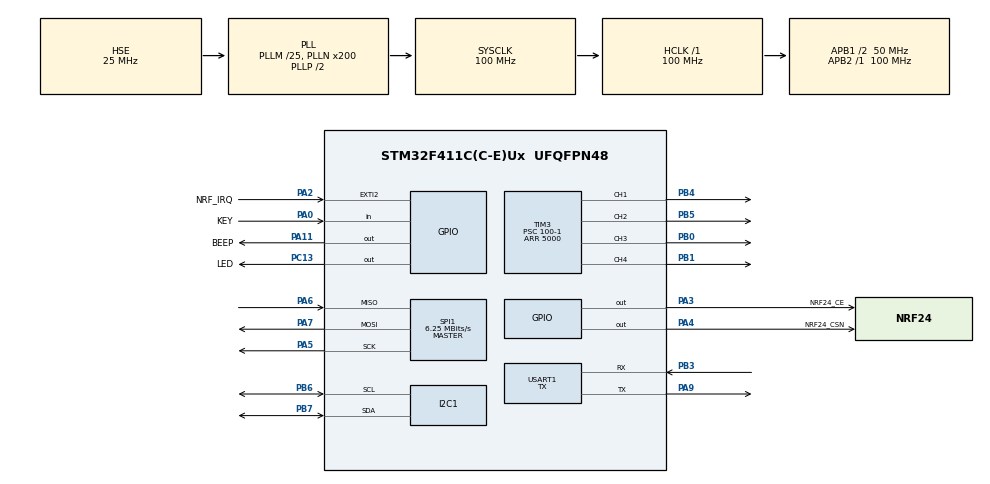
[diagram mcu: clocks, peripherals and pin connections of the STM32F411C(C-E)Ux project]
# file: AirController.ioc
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FREERTOS.BinarySemaphores01=NrfIT_Binary,Dynamic,NULL
FREERTOS.Events01=CanFlyEvent,Dynamic,NULL
FREERTOS.Queues01=rxQueue,10,12,1,Dynamic,NULL,NULL
FREERTOS.Tasks01=MainTask,42,256,StartDefaultTask,Default,NULL,Dynamic,NULL,NULL;Link2RemTask,32,512,linkTask,Default,NULL,Dynamic,NULL,NULL;ControlTask,24,512,controlTask,Default,NULL,Dynamic,NULL,NULL
FREERTOS.configENABLE_FPU=1
FREERTOS.configUSE_NEWLIB_REENTRANT=0
Mcu.Family=STM32F4
Mcu.Name=STM32F411C(C-E)Ux
Mcu.Package=UFQFPN48
NVIC.EXTI2_IRQn=true\:5\:0\:true\:false\:true\:true\:true\:true
NVIC.I2C1_ER_IRQn=true\:5\:0\:false\:false\:true\:true\:true\:true
NVIC.I2C1_EV_IRQn=true\:5\:0\:true\:false\:true\:true\:true\:true
NVIC.PriorityGroup=NVIC_PRIORITYGROUP_4
NVIC.SPI1_IRQn=true\:5\:0\:false\:false\:true\:true\:true\:true
NVIC.TIM1_UP_TIM10_IRQn=true\:0\:0\:false\:false\:true\:false\:false\:true
NVIC.TIM3_IRQn=true\:5\:0\:false\:false\:true\:true\:true\:true
NVIC.TimeBase=TIM1_UP_TIM10_IRQn
NVIC.TimeBaseIP=TIM1
PA0-WKUP.GPIO_Label=KEY
PA0-WKUP.GPIO_PuPd=GPIO_PULLUP
PA0-WKUP.Signal=GPIO_Input
PA11.GPIO_Label=BEEP
PA11.GPIO_PuPd=GPIO_PULLUP
PA11.GPIO_Speed=GPIO_SPEED_FREQ_LOW
PA11.Signal=GPIO_Output
PA13.Mode=Serial_Wire
PA13.Signal=SYS_JTMS-SWDIO
PA14.Mode=Serial_Wire
PA14.Signal=SYS_JTCK-SWCLK
PA2.GPIO_Label=NRF_IRQ
PA2.GPIO_ModeDefaultEXTI=GPIO_MODE_IT_FALLING
PA2.GPIO_PuPd=GPIO_PULLUP
PA2.Signal=GPXTI2
PA3.GPIO_Label=NRF24_CE
PA3.GPIO_ModeDefaultOutputPP=GPIO_MODE_OUTPUT_PP
PA3.GPIO_PuPd=GPIO_PULLUP
PA3.GPIO_Speed=GPIO_SPEED_FREQ_LOW
PA3.PinState=GPIO_PIN_SET
PA3.Signal=GPIO_Output
PA4.GPIO_Label=NRF24_CSN
PA4.GPIO_ModeDefaultOutputPP=GPIO_MODE_OUTPUT_PP
PA4.GPIO_PuPd=GPIO_PULLUP
PA4.GPIO_Speed=GPIO_SPEED_FREQ_LOW
PA4.PinState=GPIO_PIN_SET
PA4.Signal=GPIO_Output
PA5.Mode=Full_Duplex_Master
PA5.Signal=SPI1_SCK
PA6.Mode=Full_Duplex_Master
PA6.Signal=SPI1_MISO
PA7.Mode=Full_Duplex_Master
PA7.Signal=SPI1_MOSI
PA9.Mode=Asynchronous
PA9.Signal=USART1_TX
PB0.Signal=S_TIM3_CH3
PB1.Signal=S_TIM3_CH4
PB3.Mode=Asynchronous
PB3.Signal=USART1_RX
PB4.Signal=S_TIM3_CH1
PB5.Signal=S_TIM3_CH2
PB6.GPIO_Pu=GPIO_PULLUP
PB6.Mode=I2C
PB6.Signal=I2C1_SCL
PB7.GPIO_Pu=GPIO_PULLUP
PB7.Mode=I2C
PB7.Signal=I2C1_SDA
PC13-ANTI_TAMP.GPIO_Label=LED
PC13-ANTI_TAMP.GPIO_PuPd=GPIO_PULLDOWN
PC13-ANTI_TAMP.PinState=GPIO_PIN_SET
PC13-ANTI_TAMP.Signal=GPIO_Output
PH0\ -\ OSC_IN.Mode=HSE-External-Oscillator
PH0\ -\ OSC_IN.Signal=RCC_OSC_IN
PH1\ -\ OSC_OUT.Mode=HSE-External-Oscillator
PH1\ -\ OSC_OUT.Signal=RCC_OSC_OUT
ProjectManager.HeapSize=0x200
ProjectManager.StackSize=0x400
ProjectManager.TargetToolchain=MDK-ARM V5.32
RCC.48MHZClocksFreq_Value=40000000
RCC.AHBFreq_Value=100000000
RCC.APB1CLKDivider=RCC_HCLK_DIV2
RCC.APB1Freq_Value=50000000
RCC.APB1TimFreq_Value=100000000
RCC.APB2Freq_Value=100000000
RCC.APB2TimFreq_Value=100000000
RCC.CortexFreq_Value=100000000
RCC.HCLKFreq_Value=100000000
RCC.HSE_VALUE=25000000
RCC.HSI_VALUE=16000000
RCC.LSE_VALUE=32768
RCC.PLLM=25
RCC.PLLN=200
RCC.PLLQ=5
RCC.PLLSourceVirtual=RCC_PLLSOURCE_HSE
RCC.SYSCLKFreq_VALUE=100000000
RCC.SYSCLKSource=RCC_SYSCLKSOURCE_PLLCLK
RCC.VCOOutputFreq_Value=200000000
SH.S_TIM3_CH1.0=TIM3_CH1,PWM Generation1 CH1
SH.S_TIM3_CH2.0=TIM3_CH2,PWM Generation2 CH2
SH.S_TIM3_CH3.0=TIM3_CH3,PWM Generation3 CH3
SH.S_TIM3_CH4.0=TIM3_CH4,PWM Generation4 CH4
SPI1.BaudRatePrescaler=SPI_BAUDRATEPRESCALER_16
SPI1.CalculateBaudRate=6.25 MBits/s
SPI1.Direction=SPI_DIRECTION_2LINES
SPI1.Mode=SPI_MODE_MASTER
SPI1.VirtualType=VM_MASTER
TIM3.Channel-PWM\ Generation1\ CH1=TIM_CHANNEL_1
TIM3.Channel-PWM\ Generation2\ CH2=TIM_CHANNEL_2
TIM3.Channel-PWM\ Generation3\ CH3=TIM_CHANNEL_3
TIM3.Channel-PWM\ Generation4\ CH4=TIM_CHANNEL_4
TIM3.ClockDivision=TIM_CLOCKDIVISION_DIV1
TIM3.OCFastMode_PWM-PWM\ Generation1\ CH1=TIM_OCFAST_ENABLE
TIM3.OCFastMode_PWM-PWM\ Generation2\ CH2=TIM_OCFAST_ENABLE
TIM3.OCFastMode_PWM-PWM\ Generation3\ CH3=TIM_OCFAST_ENABLE
TIM3.OCFastMode_PWM-PWM\ Generation4\ CH4=TIM_OCFAST_ENABLE
TIM3.OCPolarity_1=TIM_OCPOLARITY_HIGH
TIM3.OCPolarity_2=TIM_OCPOLARITY_HIGH
TIM3.OCPolarity_3=TIM_OCPOLARITY_HIGH
TIM3.OCPolarity_4=TIM_OCPOLARITY_HIGH
TIM3.Period=5000
TIM3.Prescaler=100-1
TIM3.Pulse-PWM\ Generation1\ CH1=990
TIM3.Pulse-PWM\ Generation2\ CH2=990
TIM3.Pulse-PWM\ Generation3\ CH3=990
TIM3.Pulse-PWM\ Generation4\ CH4=990
USART1.Mode=MODE_TX
USART1.VirtualMode=VM_ASYNC
VP_FREERTOS_VS_CMSIS_V2.Mode=CMSIS_V2
VP_SYS_VS_tim1.Mode=TIM1
VP_TIM3_VS_ClockSourceINT.Mode=Internal
board=custom

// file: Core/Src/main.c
/* USER CODE BEGIN Header */
/**
  ******************************************************************************
  * @file           : main.c
  * @brief          : Main program body
  ******************************************************************************
  * @attention
  *
  * <h2><center>&copy; Copyright (c) 2021 STMicroelectronics.
  * All rights reserved.</center></h2>
  *
  * This software component is licensed by ST under Ultimate Liberty license
  * SLA0044, the "License"; You may not use this file except in compliance with
  * the License. You may obtain a copy of the License at:
  *                             www.st.com/SLA0044
  *
  ******************************************************************************
  */
/* USER CODE END Header */
#include "main.h"
#include "cmsis_os.h"
#include "i2c.h"
#include "spi.h"
#include "tim.h"
#include "usart.h"
#include "gpio.h"

/* USER CODE BEGIN Includes */
#include "aircraft_manager.h"
/* USER CODE END Includes */

void SystemClock_Config(void);
void MX_FREERTOS_Init(void);

int main(void)
{

  /* MCU Configuration--------------------------------------------------------*/

  /* Reset of all peripherals, Initializes the Flash interface and the Systick. */
  HAL_Init();

  /* Configure the system clock */
  SystemClock_Config();

  /* Initialize all configured peripherals */
  MX_GPIO_Init();
  MX_I2C1_Init();
  MX_SPI1_Init();
  MX_TIM3_Init();
  MX_USART1_UART_Init();
  /* USER CODE BEGIN 2 */
	HardWare_Init();
  /* USER CODE END 2 */

  /* Init scheduler */
  osKernelInitialize();  /* Call init function for freertos objects (in freertos.c) */
  MX_FREERTOS_Init();
  /* Start scheduler */
  osKernelStart();

  /* We should never get here as control is now taken by the scheduler */
  /* Infinite loop */
  while (1)
  {

  }
}

void SystemClock_Config(void)
{
  RCC_OscInitTypeDef RCC_OscInitStruct = {0};
  RCC_ClkInitTypeDef RCC_ClkInitStruct = {0};

  /** Configure the main internal regulator output voltage
  */
  __HAL_RCC_PWR_CLK_ENABLE();
  __HAL_PWR_VOLTAGESCALING_CONFIG(PWR_REGULATOR_VOLTAGE_SCALE1);
  /** Initializes the RCC Oscillators according to the specified parameters
  * in the RCC_OscInitTypeDef structure.
  */
  RCC_OscInitStruct.OscillatorType = RCC_OSCILLATORTYPE_HSE;
  RCC_OscInitStruct.HSEState = RCC_HSE_ON;
  RCC_OscInitStruct.PLL.PLLState = RCC_PLL_ON;
  RCC_OscInitStruct.PLL.PLLSource = RCC_PLLSOURCE_HSE;
  RCC_OscInitStruct.PLL.PLLM = 25;
  RCC_OscInitStruct.PLL.PLLN = 200;
  RCC_OscInitStruct.PLL.PLLP = RCC_PLLP_DIV2;
  RCC_OscInitStruct.PLL.PLLQ = 5;
  if (HAL_RCC_OscConfig(&RCC_OscInitStruct) != HAL_OK)
  {
    Error_Handler();
  }
  /** Initializes the CPU, AHB and APB buses clocks
  */
  RCC_ClkInitStruct.ClockType = RCC_CLOCKTYPE_HCLK|RCC_CLOCKTYPE_SYSCLK
                              |RCC_CLOCKTYPE_PCLK1|RCC_CLOCKTYPE_PCLK2;
  RCC_ClkInitStruct.SYSCLKSource = RCC_SYSCLKSOURCE_PLLCLK;
  RCC_ClkInitStruct.AHBCLKDivider = RCC_SYSCLK_DIV1;
  RCC_ClkInitStruct.APB1CLKDivider = RCC_HCLK_DIV2;
  RCC_ClkInitStruct.APB2CLKDivider = RCC_HCLK_DIV1;

  if (HAL_RCC_ClockConfig(&RCC_ClkInitStruct, FLASH_LATENCY_3) != HAL_OK)
  {
    Error_Handler();
  }
}

void HAL_TIM_PeriodElapsedCallback(TIM_HandleTypeDef *htim)
{
  if (htim->Instance == TIM1) {
    HAL_IncTick();
  }
}

void Error_Handler(void)
{
  __disable_irq();
  while (1)
  {
  }
}

/************************ (C) COPYRIGHT STMicroelectronics *****END OF FILE****/
